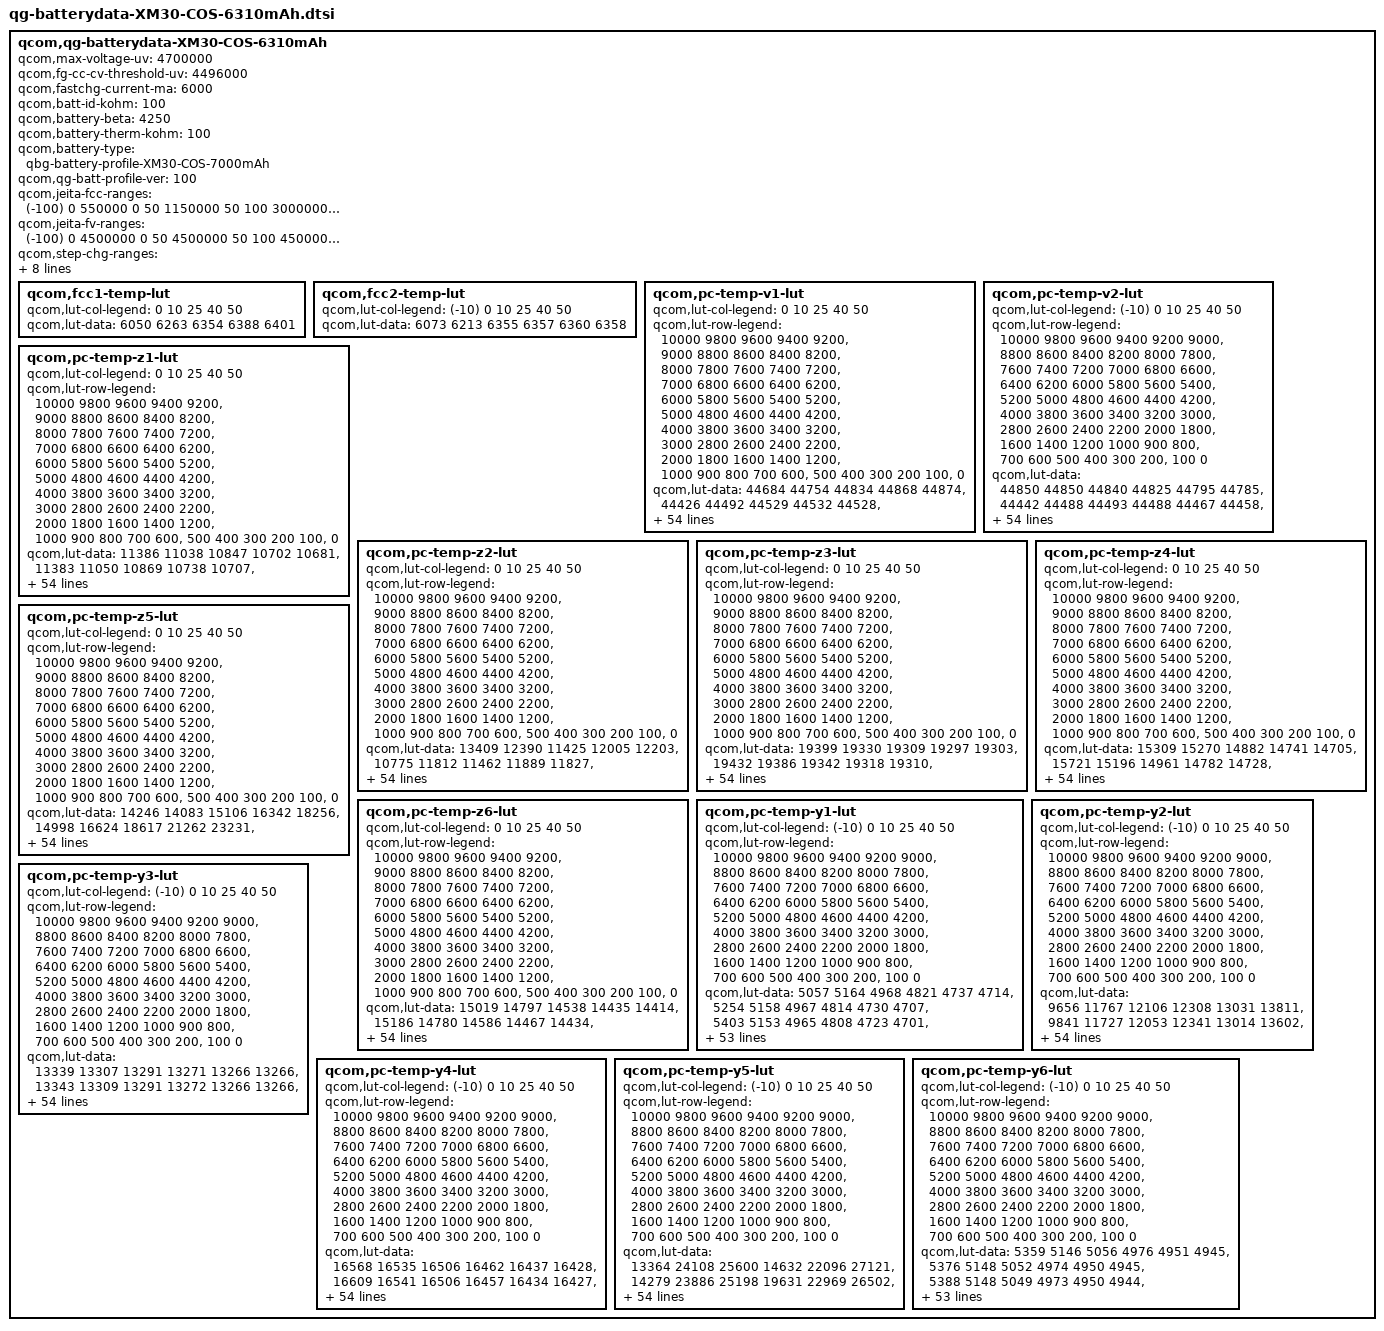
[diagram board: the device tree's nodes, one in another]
/* Copyright (c) 2018, The Linux Foundation. All rights reserved.
 *
 * This program is free software; you can redistribute it and/or modify
 * it under the terms of the GNU General Public License version 2 and
 * only version 2 as published by the Free Software Foundation.
 *
 * This program is distributed in the hope that it will be useful,
 * but WITHOUT ANY WARRANTY; without even the implied warranty of
 * MERCHANTABILITY or FITNESS FOR A PARTICULAR PURPOSE.  See the
 * GNU General Public License for more details.
 */

qcom,qg-batterydata-XM30-COS-6310mAh {
    /* 7503804_LC_M554_6310mAh_PM7250B_averaged_MasterSlave_Dec7th2024 */
    qcom,max-voltage-uv = <4700000>;
    qcom,fg-cc-cv-threshold-uv = <4496000>;
    qcom,fastchg-current-ma = <6000>;
    qcom,batt-id-kohm = <100>;
    qcom,battery-beta = <4250>;
    qcom,battery-therm-kohm = <100>;
    qcom,battery-type = "qbg-battery-profile-XM30-COS-7000mAh";
    qcom,qg-batt-profile-ver = <100>;

    qcom,jeita-fcc-ranges = <(-100)  0   550000
				0   50   1150000
				50  100  3000000
				100 150  3600000
				150 350  6000000
				350 450  6000000
				450 550  3000000
				550 1500 0>;
	qcom,jeita-fv-ranges = <(-100)   0   4500000
				0   50   4500000
				50  100  4500000
				100 150  4500000
				150 350  4560000
				350 480  4560000
				480 550  4100000
				550 1500 4100000>;
	qcom,step-chg-ranges = <3600000  4250000  6000000
				4250001  4500000  5400000
				4500001  4530000  4968000>;
	qcom,vbat-avg-based-step-chg;
	qcom,taper-fcc;

    /* COOL = 15 DegC, WARM = 45 DegC */
	qcom,jeita-soft-thresholds = <0x4621 0x20B8>;
	/* COLD = -10 DegC, HOT = 58 DegC */
	qcom,jeita-hard-thresholds = <0x6226 0x15F7>;
	/* COOL hys = 18 DegC, WARM hys = 42 DegC */
	qcom,jeita-soft-hys-thresholds = <0x4621 0x23C0>;

	qcom,jeita-soft-fcc-ua = <5400000 4500000>;
	qcom,jeita-soft-fv-uv = <4650000 4530000>;

	qcom,fcc1-temp-lut {
		qcom,lut-col-legend = <0 10 25 40 50>;
		qcom,lut-data = <6050 6263 6354 6388 6401>;
	};

	qcom,fcc2-temp-lut {
		qcom,lut-col-legend = <(-10) 0 10 25 40 50>;
		qcom,lut-data = <6073 6213 6355 6357 6360 6358>;
	};

	qcom,pc-temp-v1-lut {
		qcom,lut-col-legend = <0 10 25 40 50>;
		qcom,lut-row-legend = <10000 9800 9600 9400 9200>,
			<9000 8800 8600 8400 8200>,
			<8000 7800 7600 7400 7200>,
			<7000 6800 6600 6400 6200>,
			<6000 5800 5600 5400 5200>,
			<5000 4800 4600 4400 4200>,
			<4000 3800 3600 3400 3200>,
			<3000 2800 2600 2400 2200>,
			<2000 1800 1600 1400 1200>,
			<1000 900 800 700 600>,
			<500 400 300 200 100>,
			<0>;
		qcom,lut-data = <44684 44754 44834 44868 44874>,
			<44426 44492 44529 44532 44528>,
			<44200 44248 44288 44285 44277>,
			<43981 44026 44062 44063 44054>,
			<43764 43820 43847 43846 43837>,
			<43549 43603 43637 43637 43631>,
			<43324 43373 43413 43417 43415>,
			<43084 43136 43182 43185 43185>,
			<42838 42890 42943 42947 42949>,
			<42592 42637 42691 42700 42705>,
			<42344 42386 42434 42447 42454>,
			<42100 42140 42182 42198 42206>,
			<41861 41896 41931 41949 41956>,
			<41626 41654 41685 41704 41711>,
			<41398 41415 41445 41462 41470>,
			<41177 41186 41212 41226 41234>,
			<40962 40968 40988 40999 41006>,
			<40753 40760 40772 40780 40787>,
			<40552 40561 40566 40571 40577>,
			<40362 40369 40376 40377 40380>,
			<40187 40177 40183 40185 40188>,
			<40015 39986 39961 39972 39977>,
			<39834 39784 39719 39738 39749>,
			<39645 39532 39493 39514 39526>,
			<39446 39235 39279 39298 39306>,
			<39207 39025 39091 39103 39105>,
			<38971 38909 38950 38950 38951>,
			<38819 38816 38835 38824 38827>,
			<38718 38716 38723 38710 38713>,
			<38633 38617 38615 38604 38603>,
			<38554 38526 38515 38507 38502>,
			<38483 38442 38426 38417 38408>,
			<38417 38366 38345 38335 38321>,
			<38353 38298 38273 38258 38241>,
			<38296 38237 38208 38190 38169>,
			<38247 38182 38148 38123 38098>,
			<38207 38136 38093 38055 38019>,
			<38164 38092 38039 37986 37934>,
			<38115 38025 37969 37905 37843>,
			<38061 37933 37875 37807 37748>,
			<37984 37827 37768 37697 37641>,
			<37867 37711 37646 37574 37511>,
			<37734 37574 37505 37434 37363>,
			<37584 37399 37333 37267 37194>,
			<37414 37240 37178 37121 37055>,
			<37253 37135 37081 37034 36976>,
			<37189 37103 37058 37012 36954>,
			<37145 37084 37037 36998 36941>,
			<37114 37054 37012 36977 36919>,
			<37073 36990 36931 36876 36792>,
			<37031 36698 36604 36530 36436>,
			<36938 36206 36117 36045 35950>,
			<36602 35557 35481 35421 35321>,
			<36023 34631 34594 34548 34451>,
			<35128 33104 33162 33161 33059>,
			<30000 30000 30000 30000 30000>;
	};

	qcom,pc-temp-v2-lut {
		qcom,lut-col-legend = <(-10) 0 10 25 40 50>;
		qcom,lut-row-legend = <10000 9800 9600 9400 9200 9000>,
			<8800 8600 8400 8200 8000 7800>,
			<7600 7400 7200 7000 6800 6600>,
			<6400 6200 6000 5800 5600 5400>,
			<5200 5000 4800 4600 4400 4200>,
			<4000 3800 3600 3400 3200 3000>,
			<2800 2600 2400 2200 2000 1800>,
			<1600 1400 1200 1000 900 800>,
			<700 600 500 400 300 200>,
			<100 0>;
		qcom,lut-data = <44850 44850 44840 44825 44795 44785>,
			<44442 44488 44493 44488 44467 44458>,
			<44097 44173 44190 44190 44175 44165>,
			<43832 43917 43939 43941 43926 43916>,
			<43636 43713 43734 43735 43717 43706>,
			<43450 43514 43529 43528 43508 43495>,
			<43236 43294 43305 43302 43281 43269>,
			<43011 43068 43074 43068 43048 43036>,
			<42781 42832 42835 42826 42808 42798>,
			<42544 42583 42585 42575 42559 42550>,
			<42306 42331 42333 42323 42308 42301>,
			<42071 42087 42081 42071 42058 42052>,
			<41839 41843 41829 41820 41809 41804>,
			<41601 41607 41582 41574 41564 41560>,
			<41354 41380 41341 41332 41324 41321>,
			<41100 41153 41106 41097 41091 41088>,
			<40841 40921 40881 40869 40865 40861>,
			<40574 40685 40660 40648 40647 40642>,
			<40310 40435 40431 40439 40440 40436>,
			<40059 40157 40196 40240 40242 40239>,
			<39816 39882 39950 40023 40032 40033>,
			<39593 39639 39677 39761 39797 39805>,
			<39391 39415 39412 39495 39557 39573>,
			<39204 39218 39202 39273 39331 39348>,
			<39030 39046 39024 39074 39112 39126>,
			<38868 38889 38865 38905 38931 38944>,
			<38714 38741 38722 38764 38790 38802>,
			<38563 38601 38591 38638 38667 38680>,
			<38419 38474 38470 38520 38551 38563>,
			<38290 38360 38357 38411 38444 38455>,
			<38171 38257 38253 38311 38347 38357>,
			<38067 38154 38156 38218 38258 38266>,
			<37981 38053 38067 38133 38175 38182>,
			<37907 37964 37985 38053 38097 38102>,
			<37835 37891 37909 37978 38024 38025>,
			<37769 37826 37837 37902 37937 37932>,
			<37703 37764 37769 37825 37828 37804>,
			<37634 37707 37701 37743 37713 37670>,
			<37562 37645 37626 37652 37610 37560>,
			<37484 37572 37546 37552 37511 37458>,
			<37395 37490 37450 37446 37405 37352>,
			<37298 37386 37329 37334 37294 37239>,
			<37205 37251 37187 37206 37167 37110>,
			<37114 37103 37016 37060 37019 36959>,
			<37028 36948 36866 36923 36903 36853>,
			<36945 36831 36780 36884 36875 36825>,
			<36902 36780 36736 36865 36858 36808>,
			<36860 36728 36676 36839 36835 36786>,
			<36816 36673 36586 36797 36797 36742>,
			<36766 36619 36406 36659 36616 36521>,
			<36706 36530 36042 36283 36205 36091>,
			<36642 36352 35424 35727 35642 35520>,
			<36477 35820 34477 34993 34900 34758>,
			<36185 35131 33495 33935 33824 33653>,
			<36104 34632 31975 32111 32279 32083>,
			<36089 33768 26807 26757 27005 26951>;
	};

	qcom,pc-temp-z1-lut {
		qcom,lut-col-legend = <0 10 25 40 50>;
		qcom,lut-row-legend = <10000 9800 9600 9400 9200>,
			<9000 8800 8600 8400 8200>,
			<8000 7800 7600 7400 7200>,
			<7000 6800 6600 6400 6200>,
			<6000 5800 5600 5400 5200>,
			<5000 4800 4600 4400 4200>,
			<4000 3800 3600 3400 3200>,
			<3000 2800 2600 2400 2200>,
			<2000 1800 1600 1400 1200>,
			<1000 900 800 700 600>,
			<500 400 300 200 100>,
			<0>;
		qcom,lut-data = <11386 11038 10847 10702 10681>,
			<11383 11050 10869 10738 10707>,
			<11403 11055 10860 10734 10706>,
			<11417 11048 10849 10728 10704>,
			<11406 11030 10838 10720 10701>,
			<11381 11015 10826 10711 10694>,
			<11367 11001 10814 10702 10688>,
			<11358 10990 10801 10694 10680>,
			<11350 10981 10790 10687 10672>,
			<11337 10973 10781 10678 10665>,
			<11318 10965 10773 10669 10658>,
			<11303 10957 10766 10662 10651>,
			<11294 10951 10760 10655 10644>,
			<11288 10949 10756 10649 10638>,
			<11285 10948 10753 10646 10633>,
			<11281 10948 10750 10642 10629>,
			<11279 10944 10749 10640 10625>,
			<11280 10940 10747 10637 10622>,
			<11284 10941 10747 10636 10620>,
			<11285 10944 10746 10635 10619>,
			<11285 10947 10746 10635 10619>,
			<11285 10950 10745 10634 10618>,
			<11289 10952 10745 10634 10617>,
			<11303 10952 10745 10633 10616>,
			<11311 10950 10746 10634 10617>,
			<11309 10950 10748 10634 10618>,
			<11306 10955 10750 10635 10618>,
			<11307 10962 10752 10636 10619>,
			<11317 10965 10754 10638 10619>,
			<11325 10966 10757 10640 10621>,
			<11325 10968 10759 10642 10623>,
			<11322 10971 10761 10643 10624>,
			<11319 10975 10764 10645 10625>,
			<11318 10980 10767 10646 10626>,
			<11318 10986 10770 10649 10628>,
			<11322 10992 10773 10651 10630>,
			<11331 10998 10777 10654 10632>,
			<11339 11002 10782 10656 10633>,
			<11344 11005 10785 10659 10634>,
			<11351 11007 10788 10661 10636>,
			<11361 11010 10790 10663 10637>,
			<11378 11017 10794 10665 10638>,
			<11389 11023 10798 10667 10639>,
			<11400 11026 10798 10669 10642>,
			<11419 11031 10802 10671 10644>,
			<11415 11036 10808 10673 10646>,
			<11417 11049 10805 10673 10648>,
			<11415 11034 10810 10675 10647>,
			<11416 11041 10809 10675 10648>,
			<11417 11049 10814 10679 10649>,
			<11432 11046 10819 10682 10652>,
			<11413 11055 10825 10687 10658>,
			<11439 11070 10832 10693 10664>,
			<11460 11076 10843 10703 10672>,
			<11460 11076 10843 10703 10672>,
			<11460 11076 10843 10703 10672>;
	};

	qcom,pc-temp-z2-lut {
		qcom,lut-col-legend = <0 10 25 40 50>;
		qcom,lut-row-legend = <10000 9800 9600 9400 9200>,
			<9000 8800 8600 8400 8200>,
			<8000 7800 7600 7400 7200>,
			<7000 6800 6600 6400 6200>,
			<6000 5800 5600 5400 5200>,
			<5000 4800 4600 4400 4200>,
			<4000 3800 3600 3400 3200>,
			<3000 2800 2600 2400 2200>,
			<2000 1800 1600 1400 1200>,
			<1000 900 800 700 600>,
			<500 400 300 200 100>,
			<0>;
		qcom,lut-data = <13409 12390 11425 12005 12203>,
			<10775 11812 11462 11889 11827>,
			<11002 11462 11653 12044 12079>,
			<11168 11392 11738 12106 12262>,
			<11145 11322 11689 12056 12248>,
			<11082 11255 11618 11949 12188>,
			<11028 11180 11669 11902 12146>,
			<10981 11126 11940 11875 12114>,
			<10937 11113 12060 11859 12077>,
			<10899 11106 11790 11849 12020>,
			<10863 11130 11489 11836 11951>,
			<10846 11501 11472 11818 11910>,
			<10847 11890 11484 11782 11866>,
			<10852 11886 11505 11761 11841>,
			<10857 11717 11879 11765 11884>,
			<10865 11654 12274 11773 11961>,
			<10876 11798 12287 11780 11998>,
			<10888 11967 12246 11785 12021>,
			<10904 12041 12240 11796 12041>,
			<10951 12124 12408 11837 12072>,
			<11274 12140 12587 11906 12125>,
			<11606 11771 12474 12006 12217>,
			<11540 11362 12090 12181 12389>,
			<11190 11318 11868 12311 12474>,
			<10992 11316 11718 12421 12389>,
			<10998 11315 11616 12506 12228>,
			<11009 11304 11661 12400 12027>,
			<11015 11294 11776 12003 11723>,
			<11020 11298 11802 11708 11560>,
			<11023 11316 11668 11531 11512>,
			<11021 11325 11531 11427 11485>,
			<11017 11305 11484 11431 11511>,
			<11014 11281 11451 11469 11619>,
			<11013 11281 11451 11520 11749>,
			<11011 11295 11528 11630 11924>,
			<11008 11308 11614 11764 12100>,
			<11000 11315 11658 11891 12227>,
			<10995 11322 11695 12018 12331>,
			<10995 11338 11739 12100 12381>,
			<10996 11373 11799 12161 12398>,
			<10997 11391 11834 12199 12402>,
			<10998 11365 11829 12209 12389>,
			<10994 11342 11815 12213 12360>,
			<10970 11343 11790 12046 12320>,
			<11128 11413 11779 11967 12231>,
			<11151 11419 11708 12016 12240>,
			<11133 11402 11637 12010 12145>,
			<11056 11561 11633 12044 12310>,
			<10896 11646 11702 12222 12441>,
			<10873 11728 11760 12306 12295>,
			<10882 11591 11727 11697 11766>,
			<10814 11247 11470 11542 11583>,
			<10656 10933 11404 11466 11457>,
			<10762 10897 11141 11348 11415>,
			<10762 10897 11141 11348 11415>,
			<10762 10897 11141 11348 11415>;
	};

	qcom,pc-temp-z3-lut {
		qcom,lut-col-legend = <0 10 25 40 50>;
		qcom,lut-row-legend = <10000 9800 9600 9400 9200>,
			<9000 8800 8600 8400 8200>,
			<8000 7800 7600 7400 7200>,
			<7000 6800 6600 6400 6200>,
			<6000 5800 5600 5400 5200>,
			<5000 4800 4600 4400 4200>,
			<4000 3800 3600 3400 3200>,
			<3000 2800 2600 2400 2200>,
			<2000 1800 1600 1400 1200>,
			<1000 900 800 700 600>,
			<500 400 300 200 100>,
			<0>;
		qcom,lut-data = <19399 19330 19309 19297 19303>,
			<19432 19386 19342 19318 19310>,
			<19477 19420 19358 19324 19314>,
			<19506 19430 19365 19328 19317>,
			<19511 19436 19369 19331 19318>,
			<19514 19437 19372 19333 19320>,
			<19515 19436 19375 19333 19320>,
			<19516 19434 19379 19332 19319>,
			<19516 19430 19379 19331 19317>,
			<19515 19424 19369 19329 19316>,
			<19510 19422 19357 19326 19314>,
			<19505 19426 19352 19323 19312>,
			<19497 19431 19349 19318 19310>,
			<19489 19427 19347 19315 19308>,
			<19481 19414 19350 19314 19307>,
			<19474 19407 19352 19313 19306>,
			<19468 19406 19349 19311 19304>,
			<19463 19404 19342 19307 19301>,
			<19459 19401 19338 19304 19298>,
			<19459 19398 19334 19301 19295>,
			<19467 19395 19331 19299 19293>,
			<19476 19390 19334 19300 19293>,
			<19475 19387 19342 19304 19296>,
			<19466 19388 19344 19309 19301>,
			<19460 19393 19334 19316 19315>,
			<19465 19395 19324 19323 19331>,
			<19472 19390 19327 19328 19331>,
			<19474 19383 19337 19334 19324>,
			<19471 19383 19345 19336 19318>,
			<19469 19387 19352 19331 19315>,
			<19466 19390 19357 19324 19312>,
			<19464 19393 19355 19319 19309>,
			<19463 19395 19350 19314 19305>,
			<19463 19394 19346 19310 19302>,
			<19463 19392 19341 19306 19297>,
			<19462 19390 19338 19303 19294>,
			<19461 19389 19335 19302 19294>,
			<19458 19387 19333 19301 19294>,
			<19456 19386 19332 19301 19295>,
			<19454 19386 19331 19303 19295>,
			<19450 19385 19330 19306 19296>,
			<19446 19381 19329 19305 19297>,
			<19441 19378 19328 19303 19299>,
			<19436 19376 19329 19305 19302>,
			<19405 19366 19326 19303 19301>,
			<19399 19355 19320 19296 19291>,
			<19398 19350 19313 19296 19290>,
			<19375 19299 19312 19291 19284>,
			<19308 19298 19313 19288 19280>,
			<19305 19293 19307 19288 19290>,
			<19301 19298 19311 19303 19297>,
			<19301 19319 19316 19307 19300>,
			<19323 19338 19315 19304 19300>,
			<19432 19390 19324 19311 19303>,
			<19432 19390 19324 19311 19303>,
			<19432 19390 19324 19311 19303>;
	};

	qcom,pc-temp-z4-lut {
		qcom,lut-col-legend = <0 10 25 40 50>;
		qcom,lut-row-legend = <10000 9800 9600 9400 9200>,
			<9000 8800 8600 8400 8200>,
			<8000 7800 7600 7400 7200>,
			<7000 6800 6600 6400 6200>,
			<6000 5800 5600 5400 5200>,
			<5000 4800 4600 4400 4200>,
			<4000 3800 3600 3400 3200>,
			<3000 2800 2600 2400 2200>,
			<2000 1800 1600 1400 1200>,
			<1000 900 800 700 600>,
			<500 400 300 200 100>,
			<0>;
		qcom,lut-data = <15309 15270 14882 14741 14705>,
			<15721 15196 14961 14782 14728>,
			<15540 15116 14890 14759 14717>,
			<15338 15022 14827 14732 14702>,
			<15198 14920 14788 14715 14691>,
			<15075 14851 14755 14700 14680>,
			<14983 14806 14724 14687 14671>,
			<14915 14772 14695 14674 14662>,
			<14861 14745 14681 14666 14656>,
			<14820 14722 14680 14661 14652>,
			<14785 14700 14680 14658 14650>,
			<14760 14672 14676 14656 14647>,
			<14740 14652 14671 14654 14644>,
			<14724 14650 14664 14651 14642>,
			<14715 14655 14650 14647 14638>,
			<14709 14657 14638 14641 14634>,
			<14704 14648 14636 14638 14631>,
			<14700 14639 14635 14635 14628>,
			<14695 14636 14634 14632 14625>,
			<14687 14633 14632 14629 14623>,
			<14663 14632 14630 14627 14620>,
			<14642 14641 14638 14631 14625>,
			<14644 14658 14661 14652 14645>,
			<14663 14690 14686 14669 14657>,
			<14686 14744 14722 14680 14657>,
			<14723 14767 14748 14687 14654>,
			<14760 14758 14740 14682 14653>,
			<14766 14742 14716 14665 14651>,
			<14758 14727 14696 14654 14648>,
			<14748 14712 14677 14650 14644>,
			<14738 14698 14664 14648 14640>,
			<14728 14686 14657 14644 14636>,
			<14719 14676 14653 14640 14633>,
			<14713 14672 14651 14637 14630>,
			<14707 14670 14649 14634 14627>,
			<14702 14668 14648 14632 14626>,
			<14698 14666 14649 14634 14629>,
			<14693 14665 14650 14638 14636>,
			<14687 14666 14652 14640 14639>,
			<14679 14669 14658 14642 14637>,
			<14674 14671 14662 14643 14635>,
			<14671 14664 14656 14641 14633>,
			<14666 14656 14649 14637 14629>,
			<14657 14653 14647 14637 14628>,
			<14655 14646 14643 14635 14626>,
			<14657 14640 14634 14631 14623>,
			<14658 14639 14632 14623 14616>,
			<14682 14687 14621 14615 14610>,
			<14753 14684 14611 14607 14604>,
			<14755 14688 14622 14615 14606>,
			<14756 14696 14633 14610 14607>,
			<14758 14683 14630 14610 14607>,
			<14753 14673 14634 14613 14609>,
			<14671 14643 14631 14609 14609>,
			<14671 14643 14631 14609 14609>,
			<14671 14643 14631 14609 14609>;
	};

	qcom,pc-temp-z5-lut {
		qcom,lut-col-legend = <0 10 25 40 50>;
		qcom,lut-row-legend = <10000 9800 9600 9400 9200>,
			<9000 8800 8600 8400 8200>,
			<8000 7800 7600 7400 7200>,
			<7000 6800 6600 6400 6200>,
			<6000 5800 5600 5400 5200>,
			<5000 4800 4600 4400 4200>,
			<4000 3800 3600 3400 3200>,
			<3000 2800 2600 2400 2200>,
			<2000 1800 1600 1400 1200>,
			<1000 900 800 700 600>,
			<500 400 300 200 100>,
			<0>;
		qcom,lut-data = <14246 14083 15106 16342 18256>,
			<14998 16624 18617 21262 23231>,
			<16329 18627 20720 23235 25480>,
			<17604 19993 22285 24546 27385>,
			<18423 21063 23459 25569 28069>,
			<19109 22047 24492 26455 28463>,
			<19940 22951 26118 27180 29032>,
			<21022 23880 28545 28279 30052>,
			<22206 24896 29494 29062 30946>,
			<23374 26068 28147 29261 31291>,
			<24575 27954 26612 29354 31385>,
			<25727 32643 26587 29106 31325>,
			<26976 37233 27113 27851 30886>,
			<28050 38251 27904 27051 30738>,
			<28486 37297 34131 28113 31875>,
			<28689 36813 40511 29882 33505>,
			<28906 37436 40147 30593 33804>,
			<29474 38528 37769 30615 33374>,
			<30657 39877 36521 30538 33112>,
			<32694 41437 36769 30800 33920>,
			<39586 42348 37862 31487 35103>,
			<46499 42697 43138 33056 35284>,
			<47771 42966 53812 36035 34998>,
			<47808 43989 56304 37255 34577>,
			<48207 46344 39705 31165 33402>,
			<53887 47176 24093 23936 31704>,
			<61596 39539 23502 24606 30204>,
			<62250 30636 23784 29109 28634>,
			<55403 29862 24623 31544 28061>,
			<48475 30776 29533 31872 29180>,
			<45402 32192 35362 31890 31011>,
			<43178 35810 39036 32364 32784>,
			<42610 40528 42119 33789 34964>,
			<43942 43957 44797 35005 36760>,
			<45738 46891 47652 37118 38406>,
			<46671 49042 49280 38816 39439>,
			<47305 50553 49245 38573 39060>,
			<47908 51666 49007 37830 37943>,
			<49269 52407 47984 37558 37327>,
			<50855 53137 42521 37214 36284>,
			<50912 53429 38137 36672 35436>,
			<48467 49300 37717 35660 37620>,
			<45578 44558 37417 34224 41726>,
			<42363 43040 35646 33378 43522>,
			<34360 39986 34234 30610 39231>,
			<32182 33251 33185 26423 27711>,
			<30515 29682 28043 28949 30703>,
			<24234 15039 30122 29050 30022>,
			<13566 14872 36703 32787 33384>,
			<13303 14538 26911 26515 39699>,
			<13098 14771 22439 34611 46260>,
			<13056 16712 23840 40126 51520>,
			<14644 19243 22242 31349 45934>,
			<31845 41518 25634 43853 46510>,
			<31845 41518 25634 43853 46510>,
			<31845 41518 25634 43853 46510>;
	};

	qcom,pc-temp-z6-lut {
		qcom,lut-col-legend = <0 10 25 40 50>;
		qcom,lut-row-legend = <10000 9800 9600 9400 9200>,
			<9000 8800 8600 8400 8200>,
			<8000 7800 7600 7400 7200>,
			<7000 6800 6600 6400 6200>,
			<6000 5800 5600 5400 5200>,
			<5000 4800 4600 4400 4200>,
			<4000 3800 3600 3400 3200>,
			<3000 2800 2600 2400 2200>,
			<2000 1800 1600 1400 1200>,
			<1000 900 800 700 600>,
			<500 400 300 200 100>,
			<0>;
		qcom,lut-data = <15019 14797 14538 14435 14414>,
			<15186 14780 14586 14467 14434>,
			<15111 14756 14562 14459 14431>,
			<15023 14718 14538 14449 14427>,
			<14953 14667 14520 14442 14422>,
			<14887 14630 14504 14436 14417>,
			<14836 14604 14490 14429 14412>,
			<14797 14584 14479 14422 14407>,
			<14765 14565 14469 14416 14402>,
			<14738 14549 14461 14411 14398>,
			<14714 14537 14454 14407 14395>,
			<14696 14527 14448 14403 14391>,
			<14680 14520 14442 14398 14388>,
			<14668 14515 14438 14395 14385>,
			<14659 14511 14433 14391 14382>,
			<14652 14507 14429 14388 14379>,
			<14647 14502 14424 14385 14376>,
			<14643 14498 14421 14381 14372>,
			<14640 14494 14418 14378 14369>,
			<14637 14491 14415 14375 14366>,
			<14634 14490 14413 14372 14363>,
			<14631 14493 14418 14374 14365>,
			<14632 14497 14431 14386 14374>,
			<14637 14511 14443 14396 14384>,
			<14645 14538 14453 14406 14393>,
			<14664 14550 14460 14412 14400>,
			<14686 14544 14459 14412 14399>,
			<14690 14535 14455 14409 14395>,
			<14687 14530 14451 14405 14391>,
			<14684 14526 14447 14401 14387>,
			<14680 14523 14444 14397 14384>,
			<14676 14521 14441 14393 14381>,
			<14674 14519 14437 14389 14378>,
			<14674 14518 14435 14386 14375>,
			<14674 14517 14432 14382 14371>,
			<14674 14517 14431 14380 14369>,
			<14674 14518 14431 14380 14370>,
			<14674 14518 14431 14382 14373>,
			<14674 14520 14432 14383 14374>,
			<14675 14524 14435 14386 14374>,
			<14677 14525 14438 14388 14374>,
			<14680 14523 14436 14386 14374>,
			<14681 14522 14433 14384 14374>,
			<14682 14522 14434 14385 14375>,
			<14677 14518 14432 14384 14374>,
			<14678 14513 14426 14379 14368>,
			<14679 14510 14422 14376 14365>,
			<14679 14505 14417 14370 14359>,
			<14676 14505 14414 14365 14354>,
			<14677 14507 14417 14369 14360>,
			<14678 14516 14425 14376 14366>,
			<14686 14525 14430 14379 14369>,
			<14700 14536 14433 14380 14371>,
			<14727 14557 14441 14385 14375>,
			<14727 14557 14441 14385 14375>,
			<14727 14557 14441 14385 14375>;
	};

	qcom,pc-temp-y1-lut {
		qcom,lut-col-legend = <(-10) 0 10 25 40 50>;
		qcom,lut-row-legend = <10000 9800 9600 9400 9200 9000>,
			<8800 8600 8400 8200 8000 7800>,
			<7600 7400 7200 7000 6800 6600>,
			<6400 6200 6000 5800 5600 5400>,
			<5200 5000 4800 4600 4400 4200>,
			<4000 3800 3600 3400 3200 3000>,
			<2800 2600 2400 2200 2000 1800>,
			<1600 1400 1200 1000 900 800>,
			<700 600 500 400 300 200>,
			<100 0>;
		qcom,lut-data = <5057 5164 4968 4821 4737 4714>,
			<5254 5158 4967 4814 4730 4707>,
			<5403 5153 4965 4808 4723 4701>,
			<5506 5147 4961 4802 4717 4695>,
			<5566 5142 4957 4796 4711 4689>,
			<5586 5137 4953 4790 4705 4684>,
			<5548 5132 4948 4784 4699 4680>,
			<5460 5127 4943 4778 4694 4675>,
			<5424 5124 4936 4771 4689 4671>,
			<5429 5121 4927 4765 4684 4667>,
			<5437 5119 4919 4760 4680 4663>,
			<5435 5116 4912 4754 4676 4659>,
			<5429 5113 4907 4749 4673 4657>,
			<5424 5109 4904 4746 4670 4654>,
			<5431 5105 4902 4743 4668 4652>,
			<5443 5102 4900 4741 4666 4651>,
			<5444 5101 4897 4738 4663 4649>,
			<5435 5101 4894 4736 4660 4648>,
			<5426 5102 4892 4735 4660 4648>,
			<5427 5105 4889 4734 4660 4647>,
			<5430 5109 4888 4734 4660 4647>,
			<5431 5109 4889 4734 4660 4645>,
			<5423 5109 4890 4734 4660 4643>,
			<5414 5108 4890 4734 4660 4644>,
			<5412 5105 4890 4733 4660 4647>,
			<5411 5102 4890 4733 4660 4648>,
			<5410 5103 4890 4734 4659 4647>,
			<5418 5105 4889 4734 4659 4646>,
			<5430 5107 4890 4735 4660 4646>,
			<5430 5105 4892 4736 4661 4647>,
			<5417 5102 4893 4737 4661 4647>,
			<5406 5103 4896 4738 4662 4648>,
			<5407 5107 4898 4739 4662 4649>,
			<5412 5109 4899 4740 4663 4650>,
			<5417 5109 4902 4742 4665 4651>,
			<5427 5108 4903 4744 4666 4652>,
			<5436 5109 4901 4745 4666 4652>,
			<5432 5114 4898 4747 4667 4653>,
			<5416 5117 4898 4748 4668 4653>,
			<5405 5114 4899 4750 4670 4655>,
			<5399 5108 4901 4752 4671 4655>,
			<5394 5108 4905 4753 4673 4656>,
			<5397 5116 4909 4754 4674 4656>,
			<5417 5119 4911 4754 4675 4658>,
			<5426 5120 4923 4759 4674 4660>,
			<5415 5117 4920 4759 4676 4660>,
			<5417 5114 4926 4759 4677 4660>,
			<5434 5115 4935 4762 4677 4661>,
			<5441 5115 4930 4761 4677 4660>,
			<5456 5131 4928 4764 4678 4661>,
			<5487 5165 4944 4770 4679 4664>,
			<5541 5222 5004 4775 4684 4667>,
			<5637 5342 5112 4785 4689 4672>,
			<5779 5425 5389 4805 4697 4679>,
			<5779 5425 5389 4805 4697 4679>,
			<5779 5425 5389 4805 4697 4679>;
	};

	qcom,pc-temp-y2-lut {
		qcom,lut-col-legend = <(-10) 0 10 25 40 50>;
		qcom,lut-row-legend = <10000 9800 9600 9400 9200 9000>,
			<8800 8600 8400 8200 8000 7800>,
			<7600 7400 7200 7000 6800 6600>,
			<6400 6200 6000 5800 5600 5400>,
			<5200 5000 4800 4600 4400 4200>,
			<4000 3800 3600 3400 3200 3000>,
			<2800 2600 2400 2200 2000 1800>,
			<1600 1400 1200 1000 900 800>,
			<700 600 500 400 300 200>,
			<100 0>;
		qcom,lut-data = <9656 11767 12106 12308 13031 13811>,
			<9841 11727 12053 12341 13014 13602>,
			<10192 11687 12002 12339 12964 13382>,
			<10600 11648 11951 12313 12887 13168>,
			<10956 11613 11901 12274 12788 12979>,
			<11151 11582 11851 12232 12675 12831>,
			<11176 11555 11797 12161 12506 12715>,
			<11186 11530 11748 12084 12344 12615>,
			<11194 11511 11722 12060 12308 12535>,
			<11206 11494 11703 12047 12322 12467>,
			<11223 11484 11696 12042 12320 12403>,
			<11247 11501 11709 12053 12235 12335>,
			<11287 11548 11736 12075 12137 12278>,
			<11322 11596 11768 12104 12138 12255>,
			<11347 11656 11813 12148 12189 12256>,
			<11368 11702 11869 12190 12218 12273>,
			<11374 11715 11965 12219 12218 12299>,
			<11373 11722 12052 12251 12217 12324>,
			<11369 11724 12061 12331 12262 12337>,
			<11360 11711 12058 12481 12428 12347>,
			<11347 11697 12052 12547 12578 12376>,
			<11341 11699 12013 12506 12705 12571>,
			<11342 11709 11970 12445 12806 12799>,
			<11344 11718 11973 12401 12843 12874>,
			<11341 11736 11998 12357 12876 12922>,
			<11333 11755 12024 12345 12899 12937>,
			<11323 11762 12050 12447 12881 12951>,
			<11118 11772 12076 12570 12860 12981>,
			<10780 11778 12096 12604 12911 13035>,
			<10593 11775 12112 12625 13033 13127>,
			<10268 11770 12117 12634 13110 13222>,
			<9983 11771 12108 12645 13142 13331>,
			<9883 11776 12097 12655 13166 13420>,
			<9818 11774 12087 12641 13197 13462>,
			<9777 11746 12070 12595 13233 13492>,
			<9749 11693 12055 12559 13223 13498>,
			<9727 11629 12006 12528 13131 13464>,
			<9711 11535 11950 12503 13025 13401>,
			<9699 11422 11909 12491 12957 13254>,
			<9689 11308 11844 12479 12905 13016>,
			<9682 11168 11766 12467 12881 12953>,
			<9676 10894 11641 12456 12777 13070>,
			<9671 10217 11449 12428 12762 13120>,
			<9668 9847 11097 12377 12826 13091>,
			<9665 9721 10689 12291 12709 12865>,
			<9662 9682 10301 12168 12535 12755>,
			<9660 9672 10207 12204 12437 12568>,
			<9658 9665 9903 12176 12306 12416>,
			<9657 9660 9716 12036 12308 12293>,
			<9654 9656 9667 12001 12234 12220>,
			<9652 9653 9659 11843 12110 12149>,
			<9651 9652 9655 11561 12116 12032>,
			<9651 9652 9654 11373 11978 11968>,
			<9651 9653 9653 11084 11705 11702>,
			<9651 9653 9653 11084 11705 11702>,
			<9651 9653 9653 11084 11705 11702>;
	};

	qcom,pc-temp-y3-lut {
		qcom,lut-col-legend = <(-10) 0 10 25 40 50>;
		qcom,lut-row-legend = <10000 9800 9600 9400 9200 9000>,
			<8800 8600 8400 8200 8000 7800>,
			<7600 7400 7200 7000 6800 6600>,
			<6400 6200 6000 5800 5600 5400>,
			<5200 5000 4800 4600 4400 4200>,
			<4000 3800 3600 3400 3200 3000>,
			<2800 2600 2400 2200 2000 1800>,
			<1600 1400 1200 1000 900 800>,
			<700 600 500 400 300 200>,
			<100 0>;
		qcom,lut-data = <13339 13307 13291 13271 13266 13266>,
			<13343 13309 13291 13272 13266 13266>,
			<13351 13311 13291 13273 13266 13265>,
			<13360 13312 13291 13274 13267 13265>,
			<13367 13314 13292 13275 13267 13265>,
			<13371 13316 13293 13276 13268 13266>,
			<13372 13319 13294 13276 13268 13266>,
			<13372 13321 13295 13276 13268 13267>,
			<13372 13321 13296 13277 13269 13267>,
			<13372 13321 13298 13277 13270 13268>,
			<13372 13320 13299 13277 13270 13269>,
			<13372 13320 13298 13278 13270 13269>,
			<13372 13319 13298 13279 13271 13269>,
			<13371 13319 13297 13279 13271 13269>,
			<13370 13320 13297 13279 13271 13270>,
			<13367 13320 13297 13279 13271 13270>,
			<13364 13320 13297 13280 13272 13269>,
			<13360 13319 13297 13281 13273 13269>,
			<13355 13318 13297 13281 13274 13270>,
			<13351 13315 13296 13282 13275 13271>,
			<13346 13311 13295 13282 13276 13272>,
			<13344 13308 13292 13281 13275 13272>,
			<13342 13306 13289 13278 13274 13272>,
			<13341 13305 13288 13276 13272 13271>,
			<13339 13305 13287 13274 13269 13268>,
			<13338 13305 13286 13273 13267 13266>,
			<13337 13304 13286 13274 13267 13266>,
			<13332 13302 13286 13274 13267 13266>,
			<13325 13301 13286 13274 13267 13266>,
			<13322 13301 13286 13274 13267 13266>,
			<13320 13302 13286 13273 13267 13267>,
			<13319 13302 13286 13273 13267 13267>,
			<13322 13301 13285 13274 13267 13267>,
			<13328 13300 13285 13274 13268 13266>,
			<13334 13301 13285 13274 13268 13266>,
			<13343 13302 13286 13274 13268 13266>,
			<13354 13303 13285 13274 13267 13266>,
			<13369 13304 13285 13274 13267 13265>,
			<13390 13305 13286 13274 13267 13265>,
			<13417 13308 13286 13272 13267 13265>,
			<13455 13313 13287 13271 13267 13265>,
			<13509 13318 13289 13271 13267 13266>,
			<13583 13322 13290 13271 13267 13266>,
			<13700 13332 13292 13273 13267 13267>,
			<13877 13364 13292 13272 13267 13266>,
			<14196 13443 13299 13275 13269 13268>,
			<14426 13524 13310 13275 13268 13269>,
			<14753 13702 13334 13276 13271 13270>,
			<15162 14118 13408 13281 13274 13271>,
			<16269 15046 13681 13282 13272 13269>,
			<19440 17920 14742 13280 13271 13269>,
			<26872 27744 19494 13282 13272 13269>,
			<47842 65535 43340 13288 13272 13270>,
			<65535 65535 65535 13302 13275 13272>,
			<65535 65535 65535 13302 13275 13272>,
			<65535 65535 65535 13302 13275 13272>;
	};

	qcom,pc-temp-y4-lut {
		qcom,lut-col-legend = <(-10) 0 10 25 40 50>;
		qcom,lut-row-legend = <10000 9800 9600 9400 9200 9000>,
			<8800 8600 8400 8200 8000 7800>,
			<7600 7400 7200 7000 6800 6600>,
			<6400 6200 6000 5800 5600 5400>,
			<5200 5000 4800 4600 4400 4200>,
			<4000 3800 3600 3400 3200 3000>,
			<2800 2600 2400 2200 2000 1800>,
			<1600 1400 1200 1000 900 800>,
			<700 600 500 400 300 200>,
			<100 0>;
		qcom,lut-data = <16568 16535 16506 16462 16437 16428>,
			<16609 16541 16506 16457 16434 16427>,
			<16657 16554 16505 16452 16432 16426>,
			<16704 16569 16505 16447 16430 16425>,
			<16744 16582 16504 16444 16428 16424>,
			<16772 16588 16504 16443 16428 16424>,
			<16786 16588 16503 16444 16428 16424>,
			<16796 16588 16501 16446 16429 16424>,
			<16804 16589 16501 16448 16430 16424>,
			<16809 16590 16502 16450 16431 16425>,
			<16815 16593 16503 16453 16432 16426>,
			<16823 16601 16508 16455 16434 16427>,
			<16836 16617 16516 16459 16437 16429>,
			<16842 16635 16527 16464 16441 16431>,
			<16838 16662 16542 16471 16444 16433>,
			<16827 16685 16561 16479 16448 16437>,
			<16812 16692 16593 16488 16453 16441>,
			<16784 16697 16621 16501 16458 16446>,
			<16750 16696 16625 16521 16468 16453>,
			<16719 16658 16625 16554 16484 16462>,
			<16688 16604 16624 16567 16492 16470>,
			<16663 16571 16575 16543 16494 16475>,
			<16646 16544 16510 16505 16494 16479>,
			<16631 16528 16488 16478 16482 16470>,
			<16617 16521 16476 16454 16448 16441>,
			<16604 16517 16472 16444 16433 16429>,
			<16596 16514 16471 16444 16434 16429>,
			<16592 16512 16471 16444 16434 16430>,
			<16589 16511 16472 16445 16436 16431>,
			<16589 16512 16475 16451 16440 16433>,
			<16588 16515 16478 16456 16444 16437>,
			<16588 16514 16482 16461 16449 16441>,
			<16590 16508 16487 16466 16455 16446>,
			<16595 16505 16490 16471 16461 16452>,
			<16600 16507 16493 16476 16467 16457>,
			<16608 16510 16494 16477 16468 16458>,
			<16616 16517 16493 16474 16455 16447>,
			<16625 16530 16492 16469 16441 16435>,
			<16634 16542 16492 16460 16435 16431>,
			<16639 16550 16491 16447 16432 16429>,
			<16640 16556 16490 16442 16431 16428>,
			<16641 16563 16489 16443 16431 16428>,
			<16644 16574 16489 16444 16432 16428>,
			<16655 16577 16491 16445 16433 16428>,
			<16671 16570 16494 16436 16424 16421>,
			<16693 16587 16512 16442 16431 16425>,
			<16706 16594 16528 16450 16438 16429>,
			<16718 16607 16571 16459 16443 16442>,
			<16716 16639 16640 16481 16477 16488>,
			<16759 16675 16734 16491 16461 16450>,
			<17032 16955 16850 16465 16433 16430>,
			<17979 19336 18424 16467 16433 16432>,
			<18081 20425 41025 16493 16442 16439>,
			<16570 65535 65535 16550 16473 16474>,
			<16570 65535 65535 16550 16473 16474>,
			<16570 65535 65535 16550 16473 16474>;
	};

	qcom,pc-temp-y5-lut {
		qcom,lut-col-legend = <(-10) 0 10 25 40 50>;
		qcom,lut-row-legend = <10000 9800 9600 9400 9200 9000>,
			<8800 8600 8400 8200 8000 7800>,
			<7600 7400 7200 7000 6800 6600>,
			<6400 6200 6000 5800 5600 5400>,
			<5200 5000 4800 4600 4400 4200>,
			<4000 3800 3600 3400 3200 3000>,
			<2800 2600 2400 2200 2000 1800>,
			<1600 1400 1200 1000 900 800>,
			<700 600 500 400 300 200>,
			<100 0>;
		qcom,lut-data = <13364 24108 25600 14632 22096 27121>,
			<14279 23886 25198 19631 22969 26502>,
			<15967 23639 24756 22714 23395 25876>,
			<17908 23382 24305 24345 23481 25292>,
			<19577 23132 23875 24983 23333 24799>,
			<20452 22906 23497 25087 23055 24445>,
			<20469 22730 23165 23927 22437 24178>,
			<20393 22543 22832 21943 21659 24000>,
			<20357 22114 22452 20730 21237 24008>,
			<20266 20727 21945 19845 20993 24100>,
			<20164 19335 21270 19220 20663 23992>,
			<20270 18571 19993 18769 19973 23111>,
			<20775 17972 18530 18341 19109 21828>,
			<21343 17848 17656 17794 18330 20914>,
			<21938 18270 16987 17007 17535 20144>,
			<22520 18994 16741 16562 17219 19307>,
			<22803 20221 16989 16434 17356 18056>,
			<23062 22097 17550 16365 17588 17028>,
			<23223 23213 18911 16537 17758 17019>,
			<23194 23784 21956 17385 17911 17499>,
			<23134 24115 23996 18687 18289 18337>,
			<23128 24065 24879 22258 21986 21920>,
			<23432 23850 25399 25732 26041 25624>,
			<23792 23771 25422 25818 25850 25713>,
			<23897 24353 25199 25043 23996 24857>,
			<23948 25062 25097 24718 22867 24287>,
			<23901 24801 25266 25244 22332 23938>,
			<22271 23472 25455 25817 21766 23681>,
			<19667 22749 25398 25277 21107 23296>,
			<18470 23733 25164 23579 20364 22325>,
			<16444 25076 25000 22907 20122 21913>,
			<14853 25213 24728 23300 20243 21412>,
			<14633 24825 24481 23879 20480 20952>,
			<14497 24585 24849 24392 21157 21125>,
			<14468 24930 25929 25057 22470 21546>,
			<14631 25458 26469 25871 23170 22066>,
			<14848 25464 26600 27164 23321 22876>,
			<14996 24866 26676 28109 23445 23614>,
			<15201 24437 26532 27212 23833 24034>,
			<15297 24480 25995 24764 24370 24425>,
			<15026 24567 25487 23241 24577 24570>,
			<14550 24026 24957 21634 24076 25102>,
			<14180 19384 24391 21530 23834 26512>,
			<13755 16199 21752 24730 23739 30696>,
			<13588 14690 17776 23782 25200 27180>,
			<13554 14002 15999 24262 22479 24986>,
			<13505 13808 15789 21981 19356 24624>,
			<13433 13733 14880 20530 22723 26474>,
			<13429 13409 14630 23322 24831 23787>,
			<12826 13551 14189 24196 23311 23633>,
			<11515 11971 13409 23519 25312 26808>,
			<10789 9900 10600 25118 26621 26132>,
			<25488 16223 9018 25260 26969 25903>,
			<59077 27197 8873 22825 28006 27410>,
			<59077 27197 8873 22825 28006 27410>,
			<59077 27197 8873 22825 28006 27410>;
	};

	qcom,pc-temp-y6-lut {
		qcom,lut-col-legend = <(-10) 0 10 25 40 50>;
		qcom,lut-row-legend = <10000 9800 9600 9400 9200 9000>,
			<8800 8600 8400 8200 8000 7800>,
			<7600 7400 7200 7000 6800 6600>,
			<6400 6200 6000 5800 5600 5400>,
			<5200 5000 4800 4600 4400 4200>,
			<4000 3800 3600 3400 3200 3000>,
			<2800 2600 2400 2200 2000 1800>,
			<1600 1400 1200 1000 900 800>,
			<700 600 500 400 300 200>,
			<100 0>;
		qcom,lut-data = <5359 5146 5056 4976 4951 4945>,
			<5376 5148 5052 4974 4950 4945>,
			<5388 5148 5049 4973 4950 4944>,
			<5397 5147 5046 4972 4949 4944>,
			<5403 5146 5043 4970 4948 4943>,
			<5405 5145 5041 4970 4948 4943>,
			<5403 5143 5038 4969 4947 4943>,
			<5398 5140 5037 4969 4947 4943>,
			<5393 5137 5035 4969 4947 4943>,
			<5389 5133 5034 4969 4948 4943>,
			<5386 5131 5033 4969 4948 4943>,
			<5384 5131 5033 4970 4949 4944>,
			<5384 5133 5033 4971 4949 4944>,
			<5383 5135 5034 4972 4950 4945>,
			<5379 5142 5037 4974 4951 4945>,
			<5372 5147 5042 4976 4952 4946>,
			<5364 5147 5050 4978 4954 4947>,
			<5352 5147 5057 4982 4956 4948>,
			<5340 5147 5058 4989 4960 4951>,
			<5328 5133 5057 4998 4965 4954>,
			<5317 5115 5055 5002 4967 4957>,
			<5310 5104 5039 4994 4967 4958>,
			<5305 5095 5019 4981 4966 4959>,
			<5303 5091 5012 4972 4961 4956>,
			<5301 5090 5008 4963 4949 4945>,
			<5301 5089 5007 4960 4944 4940>,
			<5300 5089 5007 4961 4944 4940>,
			<5299 5089 5007 4961 4944 4940>,
			<5297 5089 5008 4962 4944 4941>,
			<5297 5091 5010 4963 4945 4942>,
			<5301 5095 5011 4964 4947 4943>,
			<5307 5097 5013 4966 4948 4944>,
			<5314 5098 5015 4968 4950 4946>,
			<5326 5100 5017 4970 4952 4947>,
			<5340 5103 5019 4972 4954 4949>,
			<5360 5110 5021 4972 4955 4949>,
			<5386 5117 5022 4972 4951 4945>,
			<5415 5126 5023 4971 4946 4942>,
			<5448 5138 5025 4968 4945 4941>,
			<5487 5154 5027 4964 4944 4940>,
			<5532 5173 5030 4962 4944 4940>,
			<5588 5194 5035 4963 4944 4940>,
			<5660 5217 5042 4963 4945 4941>,
			<5761 5253 5051 4966 4945 4942>,
			<5912 5314 5065 4963 4943 4939>,
			<6171 5438 5092 4967 4946 4942>,
			<6356 5530 5128 4970 4948 4944>,
			<6613 5693 5198 4974 4951 4949>,
			<6921 6036 5341 4984 4963 4963>,
			<7743 6726 5661 4989 4958 4950>,
			<10068 8832 6495 4981 4949 4945>,
			<15384 16119 10302 4986 4950 4946>,
			<29654 44915 33038 5003 4954 4949>,
			<65535 65535 65535 5040 4965 4962>,
			<65535 65535 65535 5040 4965 4962>,
			<65535 65535 65535 5040 4965 4962>;
	};

};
